AUTOSAR XML (schema 00050)
package /ComponentTypes
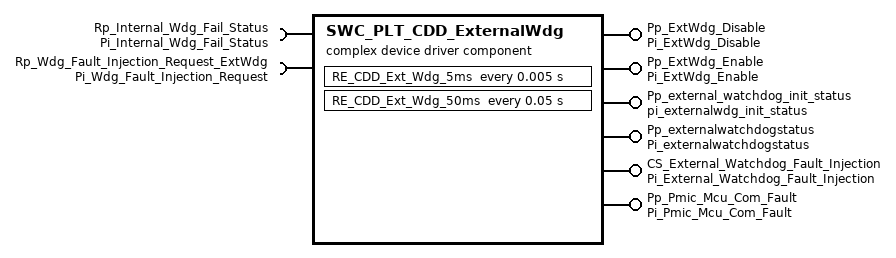
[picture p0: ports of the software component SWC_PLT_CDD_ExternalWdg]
  complex device driver sw component type SWC_PLT_CDD_ExternalWdg
    4 x provide port:
      Pp_ExtWdg_Disable: server-com-spec{operation=Operation, queue-length=1}, provided-interface=Pi_ExtWdg_Disable
      Pp_ExtWdg_Enable: server-com-spec{operation=Operation, queue-length=1}, provided-interface=Pi_ExtWdg_Enable
      Pp_external_watchdog_init_status: nonqueued-sender-com-spec{data-element=de_wdginit_status, init-value=0}, provided-interface=pi_externalwdg_init_status
      Pp_externalwatchdogstatus: nonqueued-sender-com-spec{data-element=de_externalwatchdogstatus, init-value=0}, provided-interface=Pi_externalwatchdogstatus
    require port Rp_Internal_Wdg_Fail_Status: nonqueued-receiver-com-spec{data-element=Internal_Wdg_Fail_Status, filter=data-filter-type=ALWAYS, init-value=0}, required-interface=Pi_Internal_Wdg_Fail_Status
    require port Rp_Wdg_Fault_Injection_Request_ExtWdg: nonqueued-receiver-com-spec{data-element=De_Wdg_Fault_Injection_Request, filter=data-filter-type=ALWAYS, init-value=0}, required-interface=Pi_Wdg_Fault_Injection_Request
    provide port CS_External_Watchdog_Fault_Injection: server-com-spec{operation=Read, queue-length=1}, provided-interface=Pi_External_Watchdog_Fault_Injection
    provide port Pp_Pmic_Mcu_Com_Fault: nonqueued-sender-com-spec{data-element=De_Pmic_Mcu_Com_Fault, init-value=0}, provided-interface=Pi_Pmic_Mcu_Com_Fault
    behavior SWC_PLT_CDD_ExternalWdg_InternalBehavior: handle-termination-and-restart=NO-SUPPORT
      operation invoked event OIT_Pp_ExtWdg_Disable_Operation_Pp_ExtWdg_Disable_Operation: start-on-event=CS_Pp_ExtWdg_Disable_Operation, operation=Pp_ExtWdg_Disable.Operation
      operation invoked event OIT_Pp_ExtWdg_Enable_Operation_Pp_ExtWdg_Enable_Operation: start-on-event=CS_Pp_ExtWdg_Enable_Operation, operation=Pp_ExtWdg_Enable.Operation
      timing event TMT_RE_CDD_Ext_Wdg_5ms: start-on-event=RE_CDD_Ext_Wdg_5ms, period=0.005
      init event SWC_PLT_CDD_ExternalWdg_InitEvent: start-on-event=RE_PLT_ExternalWdg_Init
      timing event TMT_RE_CDD_Ext_Wdg_50ms: start-on-event=RE_CDD_Ext_Wdg_50ms, period=0.05
      operation invoked event OIT_CS_External_Watchdog_Fault_Injection_Read_CS_External_Watchdog_Fault_Injection_Read: start-on-event=CS_External_Watchdog_Fault_Injection_Read, operation=CS_External_Watchdog_Fault_Injection.Read
      6 x runnable:
        CS_Pp_ExtWdg_Disable_Operation
        CS_Pp_ExtWdg_Enable_Operation
        RE_CDD_Ext_Wdg_5ms
          data-receive-point-by-arguments:
            access REC_Rp_Internal_Wdg_Fail_Status_Internal_Wdg_Fail_Status: accessed-variable=Rp_Internal_Wdg_Fail_Status.Internal_Wdg_Fail_Status
        RE_PLT_ExternalWdg_Init
          data-send-points:
            access SEND_Pp_external_watchdog_init_status_de_wdginit_status: accessed-variable=Pp_external_watchdog_init_status.de_wdginit_status
        RE_CDD_Ext_Wdg_50ms
          data-receive-point-by-arguments:
            access REC_Rp_Wdg_Fault_Injection_Request_ExtWdg_De_Wdg_Fault_Injection_Request: accessed-variable=Rp_Wdg_Fault_Injection_Request_ExtWdg.De_Wdg_Fault_Injection_Request
          data-send-points:
            access SEND_Pp_externalwatchdogstatus_de_externalwatchdogstatus: accessed-variable=Pp_externalwatchdogstatus.de_externalwatchdogstatus
            access SEND_Pp_Pmic_Mcu_Com_Fault_De_Pmic_Mcu_Com_Fault: accessed-variable=Pp_Pmic_Mcu_Com_Fault.De_Pmic_Mcu_Com_Fault
        CS_External_Watchdog_Fault_Injection_Read
  swc implementation SWC_PLT_CDD_ExternalWdg_Implementation: behavior=SWC_PLT_CDD_ExternalWdg_InternalBehavior
    code-descriptors:
      code Default: artifact-descriptors=autosar-engineering-object=category=SWSRC
